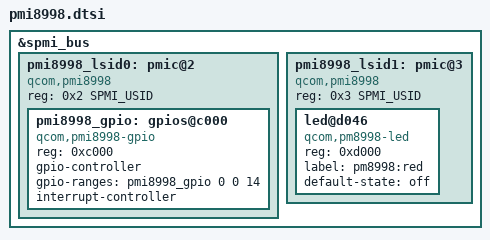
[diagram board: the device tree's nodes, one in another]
// SPDX-License-Identifier: GPL-2.0
#include <dt-bindings/interrupt-controller/irq.h>
#include <dt-bindings/spmi/spmi.h>

&spmi_bus {
	pmi8998_lsid0: pmic@2 {
		compatible = "qcom,pmi8998", "qcom,spmi-pmic";
		reg = <0x2 SPMI_USID>;
		#address-cells = <1>;
		#size-cells = <0>;

		pmi8998_gpio: gpios@c000 {
			compatible = "qcom,pmi8998-gpio", "qcom,spmi-gpio";
			reg = <0xc000>;
			gpio-controller;
			gpio-ranges = <&pmi8998_gpio 0 0 14>;
			#gpio-cells = <2>;
			interrupt-controller;
			#interrupt-cells = <2>;
		};
	};

	pmi8998_lsid1: pmic@3 {
		compatible = "qcom,pmi8998", "qcom,spmi-pmic";
		reg = <0x3 SPMI_USID>;
		#address-cells = <1>;
		#size-cells = <0>;

		led@d046 {
			status = "okay";
			compatible = "qcom,pm8998-led";
			reg = <0xd000>;
			label = "pm8998:red";
			default-state = "off";
		};
		// led@d047 {
		// 	compatible = "qcom,pm8998-led";
		// 	reg = <0xd047>;
		// 	label = "pm8998:green";
		// 	default-state = "off";
		// 	//linux,default-trigger = "mmc0";
		// };
		// led@d048 {
		// 	compatible = "qcom,pm8998-led";
		// 	reg = <0xd048>;
		// 	label = "pm8998:blue";
		// 	default-state = "on";
		// 	//linux,default-trigger = "heartbeat";
		// };
	};
};
